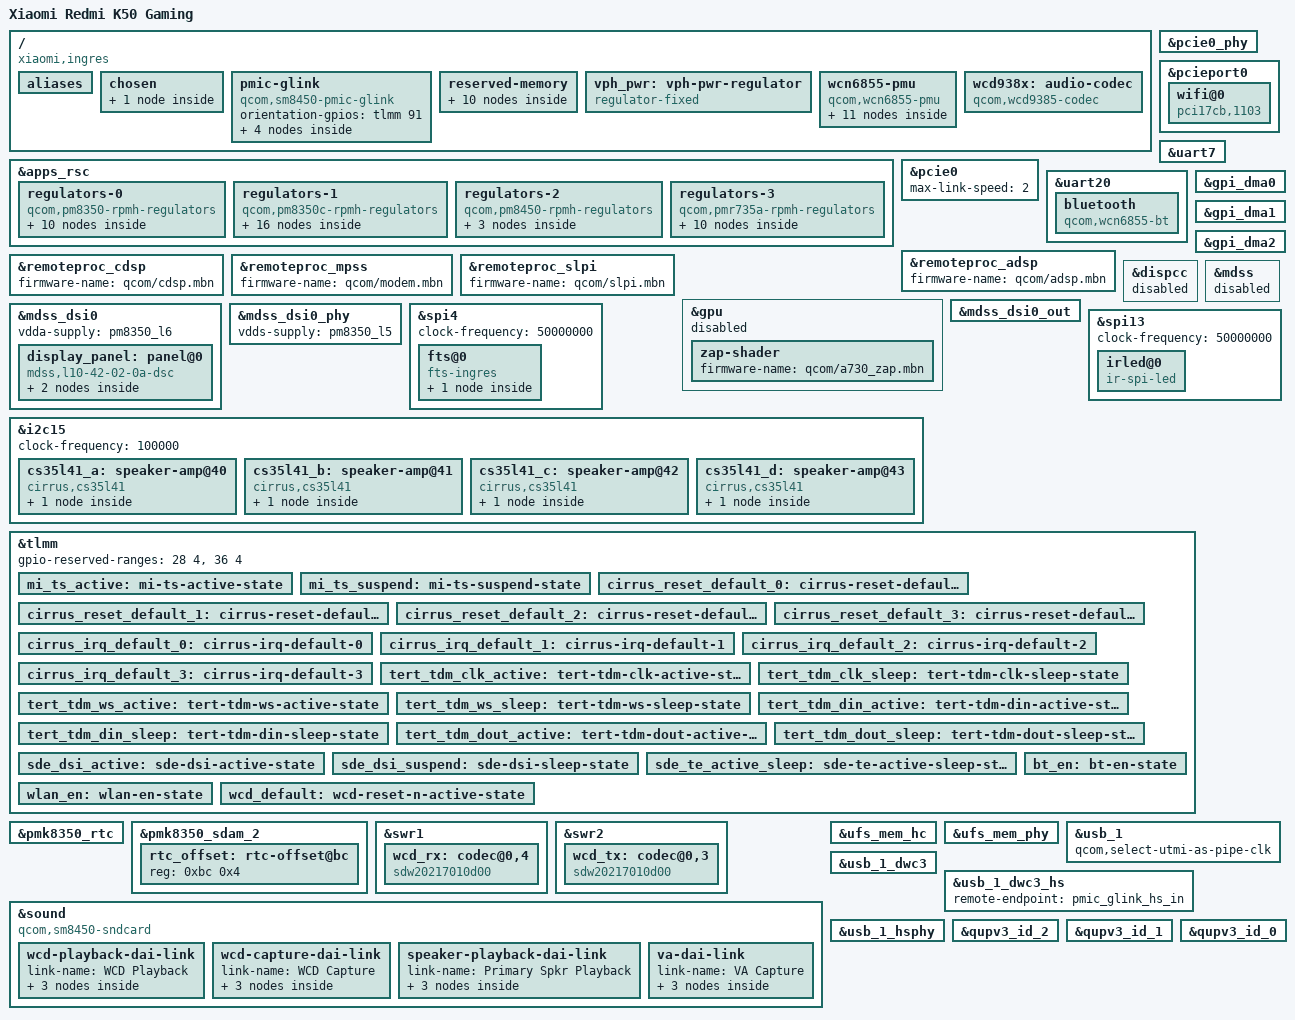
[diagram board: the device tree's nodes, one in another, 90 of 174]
// SPDX-License-Identifier: BSD-3-Clause
/*
 * Copyright (c) 2025, Nika Okromtchedlishvili <okromtchedlishvilinika@gmail.com>
 */
 
/dts-v1/;

#include <dt-bindings/leds/common.h>
#include <dt-bindings/input/linux-event-codes.h>
#include <dt-bindings/gpio/gpio.h>
#include <dt-bindings/interrupt-controller/irq.h>
#include <dt-bindings/regulator/qcom,rpmh-regulator.h>
#include <dt-bindings/leds/common.h>

#include "sm8450.dtsi"
#include "pm8350.dtsi"
#include "pm8350c.dtsi"
#include "pm8450.dtsi"
#include "pmk8350.dtsi"
#include "pmr735a.dtsi"

/delete-node/ &xbl_ramdump_mem;
/delete-node/ &xbl_sc_mem;
/delete-node/ &rmtfs_mem;
/delete-node/ &mte_mem;
/delete-node/ &trusted_apps_mem;
/delete-node/ &trusted_apps_ext_mem;

/delete-node/ &adsp_mem;
/delete-node/ &cdsp_mem;
/delete-node/ &slpi_mem;
/delete-node/ &mpss_mem;
/delete-node/ &spss_region_mem;

/ {
	model = "Xiaomi Redmi K50 Gaming";
	compatible = "xiaomi,ingres", "qcom,sm8450";
	chassis-type = "handset";
	
	aliases {
		serial0 = &uart7;
		serial1 = &uart20;
	};

	chosen {
		#address-cells = <2>;
		#size-cells = <2>;
		ranges;
		
		bootargs = "root=/dev/sda40 rootwait rw earlycon clk_ignore_unused pd_ignore_unused loglevel=8";

		framebuffer: framebuffer@b8000000 {
			compatible = "simple-framebuffer";
			reg = <0x0 0xb8000000 0x0 0x2b00000>;
			width = <1080>;
			height = <2400>;
			stride = <(1080 * 4)>;
			format = "a8r8g8b8";
			//clocks = <&gcc GCC_DISP_HF_AXI_CLK>;
		};
	};
	
	pmic-glink {
		compatible = "qcom,sm8450-pmic-glink", "qcom,pmic-glink";
		#address-cells = <1>;
		#size-cells = <0>;
		orientation-gpios = <&tlmm 91 GPIO_ACTIVE_HIGH>;

		connector@0 {
			compatible = "usb-c-connector";
			reg = <0>;
			power-role = "dual";
			data-role = "dual";

			ports {
				#address-cells = <1>;
				#size-cells = <0>;

				port@0 {
					reg = <0>;

					pmic_glink_hs_in: endpoint {
						remote-endpoint = <&usb_1_dwc3_hs>;
					};
				};
			};
		};
	};

	reserved-memory {
		xbl_ramdump_mem: memory@a6b80000 {
			no-map;
			reg = <0 0xa6b80000 0 0x280000>;
		};

		xbl_sc_mem: memory@a6e00000 {
			no-map;
			reg = <0 0xa6e00000 0 0x40000>;
		};

		framebuffer_mem: framebuffer@b8000000 {
			reg = <0x0 0xb8000000 0x0 0x2b00000>;
			no-map;
		};

		spss_region_mem: memory@8ba00000 {
			no-map;
			reg = <0 0x8ba00000 0 0x180000>;
		};

		adsp_mem: memory@9fd00000 {
			no-map;
			reg = <0 0x9fd00000 0 0x3100000>;
		};

		slpi_mem: memory@88000000 {
			no-map;
			reg = <0 0x88000000 0 0x1900000>;
		};

		cdsp_mem: memory@89900000 {
			no-map;
			reg = <0 0x89900000 0 0x2000000>;
		};

		mpss_mem: memory@8bc00000 {
			no-map;
			reg = <0 0x8bc00000 0 0x13200000>;
		};

		rmtfs_mem: memory@fe200000 {
			compatible = "qcom,rmtfs-mem";
			reg = <0x0 0xfe200000 0x0 0x280000>;
			no-map;

			qcom,client-id = <1>;
			qcom,vmid = <QCOM_SCM_VMID_MSS_MSA>;
		};

		ramoops@a7000000 {
			compatible = "ramoops";
			reg = <0 0xa7000000 0x0 0x400000>;
			console-size = <0x200000>;
			pmsg-size = <0x200000>;
			ecc-size = <16>;
			no-map;
		};
	};

	vph_pwr: vph-pwr-regulator {
		compatible = "regulator-fixed";
		regulator-name = "vph_pwr";
		regulator-min-microvolt = <3700000>;
		regulator-max-microvolt = <3700000>;

		regulator-always-on;
		regulator-boot-on;
	};
	
	wcn6855-pmu {
		compatible = "qcom,wcn6855-pmu";

		pinctrl-0 = <&wlan_en>;
		pinctrl-names = "default";

		wlan-enable-gpios = <&tlmm 80 GPIO_ACTIVE_HIGH>;
		bt-enable-gpios = <&tlmm 81 GPIO_ACTIVE_HIGH>;

		vddio-supply = <&pm8350_s10>;
		vddaon-supply = <&pmr735a_s2>;
		vddpmu-supply = <&pm8350_s11>;
		vddrfa0p95-supply = <&pm8350_s11>;
		vddrfa1p3-supply = <&pm8350_s12>;
		vddrfa1p9-supply = <&pm8350c_s1>;
		vddpcie1p3-supply = <&pm8350_s12>;
		vddpcie1p9-supply = <&pm8350c_s1>;
		

		regulators {
			vreg_pmu_rfa_cmn_0p8: ldo0 {
				regulator-name = "vreg_pmu_rfa_cmn_0p8";
			};

			vreg_pmu_aon_0p8: ldo1 {
				regulator-name = "vreg_pmu_aon_0p8";
			};

			vreg_pmu_wlcx_0p8: ldo2 {
				regulator-name = "vreg_pmu_wlcx_0p8";
			};

			vreg_pmu_wlmx_0p8: ldo3 {
				regulator-name = "vreg_pmu_wlmx_0p8";
			};

			vreg_pmu_btcmx_0p8: ldo4 {
				regulator-name = "vreg_pmu_btcmx_0p8";
			};

			vreg_pmu_pcie_1p8: ldo5 {
				regulator-name = "vreg_pmu_pcie_1p8";
			};

			vreg_pmu_pcie_0p9: ldo6 {
				regulator-name = "vreg_pmu_pcie_0p9";
			};

			vreg_pmu_rfa_0p8: ldo7 {
				regulator-name = "vreg_pmu_rfa_0p8";
			};

			vreg_pmu_rfa_1p2: ldo8 {
				regulator-name = "vreg_pmu_rfa_1p2";
			};

			vreg_pmu_rfa_1p7: ldo9 {
				regulator-name = "vreg_pmu_rfa_1p7";
			};
		};
	};
	
	wcd938x: audio-codec {
		compatible = "qcom,wcd9385-codec";

		pinctrl-names = "default";
		pinctrl-0 = <&wcd_default>;

		qcom,micbias1-microvolt = <2750000>;
		qcom,micbias2-microvolt = <2750000>;
		qcom,micbias3-microvolt = <2750000>;
		qcom,micbias4-microvolt = <2750000>;
		qcom,mbhc-buttons-vthreshold-microvolt = <75000 150000 237000 500000 500000 500000 500000 500000>;
		qcom,mbhc-headset-vthreshold-microvolt = <1700000>;
		qcom,mbhc-headphone-vthreshold-microvolt = <50000>;
		qcom,rx-device = <&wcd_rx>;
		qcom,tx-device = <&wcd_tx>;

		reset-gpios = <&tlmm 43 GPIO_ACTIVE_LOW>;

		vdd-buck-supply = <&pm8350_s10>;
		vdd-rxtx-supply = <&pm8350_s10>;
		vdd-io-supply = <&pm8350_s10>;
		vdd-mic-bias-supply = <&vreg_bob>;

		#sound-dai-cells = <1>;
	};
	
};

&apps_rsc {
	regulators-0 {
		compatible = "qcom,pm8350-rpmh-regulators";
		qcom,pmic-id = "b";

		vdd-s1-supply = <&vph_pwr>;
		vdd-s2-supply = <&vph_pwr>;
		vdd-s3-supply = <&vph_pwr>;
		vdd-s4-supply = <&vph_pwr>;
		vdd-s5-supply = <&vph_pwr>;
		vdd-s6-supply = <&vph_pwr>;
		vdd-s7-supply = <&vph_pwr>;
		vdd-s8-supply = <&vph_pwr>;
		vdd-s9-supply = <&vph_pwr>;
		vdd-s10-supply = <&vph_pwr>;
		vdd-s11-supply = <&vph_pwr>;
		vdd-s12-supply = <&vph_pwr>;

		vdd-l1-l4-supply = <&pm8350_s11>;
		vdd-l2-l7-supply = <&vreg_bob>;
		vdd-l3-l5-supply = <&pm8350_s11>;
		vdd-l6-l9-l10-supply = <&pm8350_s12>;

		/*
		 * ARC regulators:
		 * s5 - gfx.lvl
		 * l8 - lcx.lvl
		 */

		pm8350_s10: smps10 {
			regulator-name = "pm8350_s10";
			regulator-min-microvolt = <1800000>;
			regulator-max-microvolt = <1800000>;
		};

		pm8350_s11: smps11 {
			regulator-name = "pm8350_s11";
			regulator-min-microvolt = <848000>;
			regulator-max-microvolt = <1104000>;
		};

		pm8350_s12: smps12 {
			regulator-name = "pm8350_s12";
			regulator-min-microvolt = <1224000>;
			regulator-max-microvolt = <1400000>;
		};

		pm8350_l1: ldo1 {
			regulator-name = "pm8350_l1";
			regulator-min-microvolt = <912000>;
			regulator-max-microvolt = <920000>;
			regulator-initial-mode = <RPMH_REGULATOR_MODE_HPM>;
		};

		pm8350_l2: ldo2 {
			regulator-name = "pm8350_l2";
			regulator-min-microvolt = <3072000>;
			regulator-max-microvolt = <3072000>;
			regulator-initial-mode = <RPMH_REGULATOR_MODE_HPM>;
		};

		pm8350_l3: ldo3 {
			regulator-name = "pm8350_l3";
			regulator-min-microvolt = <904000>;
			regulator-max-microvolt = <904000>;
			regulator-initial-mode = <RPMH_REGULATOR_MODE_HPM>;
		};

		pm8350_l5: ldo5 {
			regulator-name = "pm8350_l5";
			regulator-min-microvolt = <880000>;
			regulator-max-microvolt = <912000>;
			regulator-initial-mode = <RPMH_REGULATOR_MODE_HPM>;
		};

		pm8350_l6: ldo6 {
			regulator-name = "pm8350_l6";
			regulator-min-microvolt = <1200000>;
			regulator-max-microvolt = <1200000>;
			regulator-initial-mode = <RPMH_REGULATOR_MODE_HPM>;
		};

		pm8350_l7: ldo7 {
			regulator-name = "pm8350_l7";
			regulator-min-microvolt = <2504000>;
			regulator-max-microvolt = <2504000>;
			regulator-initial-mode = <RPMH_REGULATOR_MODE_HPM>;
		};

		pm8350_l9: ldo9 {
			regulator-name = "pm8350_l9";
			regulator-min-microvolt = <1200000>;
			regulator-max-microvolt = <1200000>;
			regulator-initial-mode = <RPMH_REGULATOR_MODE_HPM>;
		};
	};

	regulators-1 {
		compatible = "qcom,pm8350c-rpmh-regulators";
		qcom,pmic-id = "c";

		vdd-s1-supply = <&vph_pwr>;
		vdd-s2-supply = <&vph_pwr>;
		vdd-s3-supply = <&vph_pwr>;
		vdd-s4-supply = <&vph_pwr>;
		vdd-s5-supply = <&vph_pwr>;
		vdd-s6-supply = <&vph_pwr>;
		vdd-s7-supply = <&vph_pwr>;
		vdd-s8-supply = <&vph_pwr>;
		vdd-s9-supply = <&vph_pwr>;
		vdd-s10-supply = <&vph_pwr>;

		vdd-l1-l12-supply = <&pm8350c_s1>;
		vdd-l2-l8-supply = <&pm8350c_s1>;
		vdd-l3-l4-l5-l7-l13-supply = <&vreg_bob>;
		vdd-l6-l9-l11-supply = <&vreg_bob>;
		vdd-l10-supply = <&pm8350_s12>;

		vdd-bob-supply = <&vph_pwr>;

		/*
		 * ARC regulators:
		 * s2 - mxc.lvl
		 * s4 - mss.lvl
		 * s6 - cx.lvl
		 */

		pm8350c_s1: smps1 {
			regulator-name = "pm8350c_s1";
			regulator-min-microvolt = <1800000>;
			regulator-max-microvolt = <2024000>;
		};

		pm8350c_s10: smps10 {
			regulator-name = "pm8350c_s10";
			regulator-min-microvolt = <1000000>;
			regulator-max-microvolt = <1100000>;
		};

		vreg_bob: bob {
			regulator-name = "vreg_bob";
			regulator-min-microvolt = <3080000>;
			regulator-max-microvolt = <3960000>;
			regulator-initial-mode = <RPMH_REGULATOR_MODE_AUTO>;
		};

		pm8350c_l1: ldo1 {
			regulator-name = "pm8350c_l1";
			regulator-min-microvolt = <1800000>;
			regulator-max-microvolt = <1800000>;
			regulator-initial-mode = <RPMH_REGULATOR_MODE_HPM>;
		};

		pm8350c_l2: ldo2 {
			regulator-name = "pm8350c_l2";
			regulator-min-microvolt = <1800000>;
			regulator-max-microvolt = <1800000>;
			regulator-initial-mode = <RPMH_REGULATOR_MODE_HPM>;
		};

		pm8350c_l3: ldo3 {
			regulator-name = "pm8350c_l3";
			regulator-min-microvolt = <3296000>;
			regulator-max-microvolt = <3304000>;
			regulator-initial-mode = <RPMH_REGULATOR_MODE_HPM>;
		};

		pm8350c_l4: ldo4 {
			regulator-name = "pm8350c_l4";
			regulator-min-microvolt = <1704000>;
			regulator-max-microvolt = <3000000>;
			regulator-initial-mode = <RPMH_REGULATOR_MODE_HPM>;
		};

		pm8350c_l5: ldo5 {
			regulator-name = "pm8350c_l5";
			regulator-min-microvolt = <1704000>;
			regulator-max-microvolt = <3000000>;
			regulator-initial-mode = <RPMH_REGULATOR_MODE_HPM>;
		};

		pm8350c_l6: ldo6 {
			regulator-name = "pm8350c_l6";
			regulator-min-microvolt = <1800000>;
			/* Originally max = 3008000 but SDHCI expects 2960000 */
			regulator-max-microvolt = <2960000>;
			regulator-initial-mode = <RPMH_REGULATOR_MODE_HPM>;
		};

		pm8350c_l7: ldo7 {
			regulator-name = "pm8350c_l7";
			regulator-min-microvolt = <3008000>;
			regulator-max-microvolt = <3304000>;
			regulator-initial-mode = <RPMH_REGULATOR_MODE_HPM>;
		};

		pm8350c_l8: ldo8 {
			regulator-name = "pm8350c_l8";
			regulator-min-microvolt = <1800000>;
			regulator-max-microvolt = <1800000>;
			regulator-initial-mode = <RPMH_REGULATOR_MODE_HPM>;
		};

		pm8350c_l9: ldo9 {
			regulator-name = "pm8350c_l9";
			regulator-min-microvolt = <2960000>;
			/* Originally max = 3008000 but SDHCI expects 2960000 */
			regulator-max-microvolt = <2960000>;
			regulator-initial-mode = <RPMH_REGULATOR_MODE_HPM>;
		};

		pm8350c_l10: ldo10 {
			regulator-name = "pm8350c_l10";
			regulator-min-microvolt = <1200000>;
			regulator-max-microvolt = <1220000>;
			regulator-initial-mode = <RPMH_REGULATOR_MODE_HPM>;
		};

		pm8350c_l11: ldo11 {
			regulator-name = "pm8350c_l11";
			regulator-min-microvolt = <3200000>;
			regulator-max-microvolt = <3200000>;
			regulator-initial-mode = <RPMH_REGULATOR_MODE_HPM>;

			regulator-always-on;
			regulator-boot-on;
		};

		pm8350c_l12: ldo12 {
			regulator-name = "pm8350c_l12";
			regulator-min-microvolt = <1800000>;
			regulator-max-microvolt = <1968000>;
			regulator-initial-mode = <RPMH_REGULATOR_MODE_HPM>;
		};

		pm8350c_l13: ldo13 {
			regulator-name = "pm8350c_l13";
			regulator-min-microvolt = <3000000>;
			regulator-max-microvolt = <3000000>;
			regulator-initial-mode = <RPMH_REGULATOR_MODE_HPM>;
		};
	};

	regulators-2 {
		compatible = "qcom,pm8450-rpmh-regulators";
		qcom,pmic-id = "h";

		vdd-s1-supply = <&vph_pwr>;
		vdd-s2-supply = <&vph_pwr>;
		vdd-s3-supply = <&vph_pwr>;
		vdd-s4-supply = <&vph_pwr>;
		vdd-s5-supply = <&vph_pwr>;
		vdd-s6-supply = <&vph_pwr>;

		vdd-l2-supply = <&vreg_bob>;
		vdd-l3-supply = <&vreg_bob>;
		vdd-l4-supply = <&vreg_bob>;

		/*
		 * ARC regulators:
		 * S2 - ebi.lvl
		 * S4 - mmcx.lvl
		 * S6 - mx.lvl
		 * L1 - lmx.lvl
		 */

		pm8450_s3: smps3 {
			regulator-name = "pm8450_s3";
			regulator-min-microvolt = <500000>;
			regulator-max-microvolt = <600000>;
		};

		pm8450_l2: ldo2 {
			regulator-name = "pm8450_l2";
			regulator-min-microvolt = <880000>;
			regulator-max-microvolt = <912000>;
			regulator-initial-mode = <RPMH_REGULATOR_MODE_HPM>;
		};

		pm8450_l3: ldo3 {
			regulator-name = "pm8450_l3";
			regulator-min-microvolt = <912000>;
			regulator-max-microvolt = <912000>;
			regulator-initial-mode = <RPMH_REGULATOR_MODE_HPM>;
		};
	};

	regulators-3 {
		compatible = "qcom,pmr735a-rpmh-regulators";
		qcom,pmic-id = "e";

		vdd-s1-supply = <&vph_pwr>;
		vdd-s2-supply = <&vph_pwr>;
		vdd-s3-supply = <&vph_pwr>;

		vdd-l1-l2-supply = <&pmr735a_s2>;
		vdd-l3-supply = <&pmr735a_s1>;
		vdd-l4-supply = <&pm8350c_s1>;
		vdd-l5-l6-supply = <&pm8350c_s1>;
		vdd-l7-bob-supply = <&vreg_bob>;

		pmr735a_s1: smps1 {
			regulator-name = "pmr735a_s1";
			regulator-min-microvolt = <1200000>;
			regulator-max-microvolt = <1296000>;
		};

		pmr735a_s2: smps2 {
			regulator-name = "pmr735a_s2";
			regulator-min-microvolt = <500000>;
			regulator-max-microvolt = <1040000>;
		};

		pmr735a_s3: smps3 {
			regulator-name = "pmr735a_s3";
			regulator-min-microvolt = <435000>;
			regulator-max-microvolt = <2352000>;
		};

		pmr735a_l1: ldo1 {
			regulator-name = "pmr735a_l1";
			regulator-min-microvolt = <800000>;
			regulator-max-microvolt = <800000>;
		};

		pmr735a_l2: ldo2 {
			regulator-name = "pmr735a_l2";
			regulator-min-microvolt = <480000>;
			regulator-max-microvolt = <912000>;
		};

		pmr735a_l3: ldo3 {
			regulator-name = "pmr735a_l3";
			regulator-min-microvolt = <1200000>;
			regulator-max-microvolt = <1200000>;
		};

		pmr735a_l4: ldo4 {
			regulator-name = "pmr735a_l4";
			regulator-min-microvolt = <1776000>;
			regulator-max-microvolt = <1776000>;
		};

		pmr735a_l5: ldo5 {
			regulator-name = "pmr735a_l5";
			regulator-min-microvolt = <880000>;
			regulator-max-microvolt = <880000>;
		};

		pmr735a_l6: ldo6 {
			regulator-name = "pmr735a_l6";
			regulator-min-microvolt = <1200000>;
			regulator-max-microvolt = <1200000>;
		};

		pmr735a_l7: ldo7 {
			regulator-name = "pmr735a_l7";
			regulator-min-microvolt = <2800000>;
			regulator-max-microvolt = <2800000>;
		};
	};
};

&pcie0 {
	status = "okay";
	max-link-speed = <2>;
};

&pcie0_phy {
	status = "okay";
	vdda-phy-supply = <&pm8350_l5>;
	vdda-pll-supply = <&pm8350_l6>;
};

&pcieport0 {
	wifi@0 {
		compatible = "pci17cb,1103";
		reg = <0x10000 0x0 0x0 0x0 0x0>;

		vddrfacmn-supply = <&vreg_pmu_rfa_cmn_0p8>;
		vddaon-supply = <&vreg_pmu_aon_0p8>;
		vddwlcx-supply = <&vreg_pmu_wlcx_0p8>;
		vddwlmx-supply = <&vreg_pmu_wlmx_0p8>;
		vddpcie1p8-supply = <&vreg_pmu_pcie_1p8>;
		vddpcie0p9-supply = <&vreg_pmu_pcie_0p9>;
		vddrfa0p8-supply = <&vreg_pmu_rfa_0p8>;
		vddrfa1p2-supply = <&vreg_pmu_rfa_1p2>;
		vddrfa1p8-supply = <&vreg_pmu_rfa_1p7>;
	};
};

&uart7 {
	status = "okay";
};

&uart20 {
	status = "okay";

	bluetooth {
		compatible = "qcom,wcn6855-bt";

		vddrfacmn-supply = <&vreg_pmu_rfa_cmn_0p8>;
		vddaon-supply = <&vreg_pmu_aon_0p8>;
		vddwlcx-supply = <&vreg_pmu_wlcx_0p8>;
		vddwlmx-supply = <&vreg_pmu_wlmx_0p8>;
		vddbtcmx-supply = <&vreg_pmu_btcmx_0p8>;
		vddrfa0p8-supply = <&vreg_pmu_rfa_0p8>;
		vddrfa1p2-supply = <&vreg_pmu_rfa_1p2>;
		vddrfa1p8-supply = <&vreg_pmu_rfa_1p7>;

		max-speed = <3200000>;
	};
};

&remoteproc_adsp {
	firmware-name = "qcom/adsp.mbn";
	status = "okay";
};

&remoteproc_cdsp {
	firmware-name = "qcom/cdsp.mbn";
	status = "okay";
};

&remoteproc_mpss {
	firmware-name = "qcom/modem.mbn";
	status = "okay";
};

&remoteproc_slpi {
	firmware-name = "qcom/slpi.mbn";
	status = "okay";
};

&gpi_dma0 {
	status = "okay";
};

&gpi_dma1 {
	status = "okay";
};

&gpi_dma2 {
	status = "okay";
};

&gpu {
	status = "disabled";

	zap-shader {
		firmware-name = "qcom/a730_zap.mbn";
	};
};

&dispcc {
	status = "disabled";
};

&mdss {
	status = "disabled";
};

&mdss_dsi0 {
	vdda-supply = <&pm8350_l6>;
	status = "okay";

	display_panel: panel@0 {
		compatible = "mdss,l10-42-02-0a-dsc";
		reg = <0>;

		reset-gpios = <&tlmm 0 GPIO_ACTIVE_LOW>;
		te-gpios = <&tlmm 86 GPIO_ACTIVE_HIGH>;

		pinctrl-0 = <&sde_dsi_active &sde_te_active_sleep>;
		pinctrl-1 = <&sde_dsi_suspend &sde_te_active_sleep>;
		pinctrl-names = "default", "sleep";

		vddd-supply = <&pm8350c_l10>;
		vci-supply = <&pm8350c_l13>;
		vddio-supply = <&pm8350c_l12>;

		port {
			panel_in: endpoint {
				remote-endpoint = <&mdss_dsi0_out>;
			};
		};
	};
};

&mdss_dsi0_out {
	data-lanes = <0 1 2 3>;
	remote-endpoint = <&panel_in>;
};

&mdss_dsi0_phy {
	vdds-supply = <&pm8350_l5>;
	status = "okay";
};

&spi4 {
	clock-frequency = <50000000>;
	status = "okay";

	fts@0 {
	    status = "okay";
		compatible = "fts-ingres";
		reg = <0x0>;
		interrupt-parent = <&tlmm>;
		interrupts = <21 IRQ_TYPE_LEVEL_LOW>;
		pinctrl-names = "pmx_ts_active", "pmx_ts_suspend";
		pinctrl-0 = <&mi_ts_active>;
		pinctrl-1 = <&mi_ts_suspend>;
		avdd-supply = <&pm8350c_l3>;
		vdd-supply = <&pm8350c_l2>;
		fts,pwr-reg-name = "avdd";
		fts,bus-reg-name = "vdd";
		fts,irq-gpio = <&tlmm 21 IRQ_TYPE_LEVEL_LOW>;
		fts,reset-gpio-enable;
		fts,reset-gpio = <&tlmm 20 GPIO_ACTIVE_HIGH>;
		fts,irq-flags = <IRQ_TYPE_LEVEL_LOW>;
		fts,x-max = <10800>;
		fts,y-max = <24000>;
		fts,support-super-resolution = <1>;
		spi-max-frequency = <12000000>;
		fts,default-fw-name = "st_fts_l10.ftb";
		fts,config-array-size = <1>;
		panel = <&display_panel>;

		fts,cfg_0 {
			fts,tp-vendor = <0x42>;
			fts,fw-name = "st_fts_l10.ftb";
			fts,limit-name = "stm_fts_production_limits.csv";
		};
	};
};

&spi13 {
	clock-frequency = <50000000>;
	status = "okay";

	irled@0 {
		compatible = "ir-spi-led";
		reg = <0x0>;
		power-supply = <&vph_pwr>;
		spi-max-frequency = <19200000>;
	};
};

&i2c15 {
	clock-frequency = <100000>;
	status = "okay";

	cs35l41_a: speaker-amp@40 {
		compatible = "cirrus,cs35l41";
		reg = <0x40>;
		interrupt-parent = <&tlmm>;
		interrupts = <117 0x2008>;
		pinctrl-names = "default";
		pinctrl-0 = <&cirrus_reset_default_0 &cirrus_irq_default_0>;
		reset-gpios = <&tlmm 120 0>;
		cirrus,boost-peak-milliamp = <4000>;
		cirrus,boost-ind-nanohenry = <1000>;
		cirrus,boost-cap-microfarad = <15>;
		cirrus,gpio2-src-select = <4>;
		cirrus,gpio2-output-enable;
		cirrus,asp-sdout-hiz = <3>;
		cirrus,fast-switch = "BH-music.txt", "BH-handfree.txt";
		sound-name-prefix = "BH";
		#sound-dai-cells = <1>;
		cirrus,gpio-config2 {
			cirrus,gpio-src-select = <0x04>;
			cirrus,gpio-output-enable;
		};
	};
	
	cs35l41_b: speaker-amp@41 {
		compatible = "cirrus,cs35l41";
		reg = <0x41>;
		interrupt-parent = <&tlmm>;
		interrupts = <118 0x2008>;
		pinctrl-names = "default";
		pinctrl-0 = <&cirrus_reset_default_1 &cirrus_irq_default_1>;
		reset-gpios = <&tlmm 9 0>;
		cirrus,boost-peak-milliamp = <4000>;
		cirrus,boost-ind-nanohenry = <1000>;
		cirrus,boost-cap-microfarad = <15>;
		cirrus,gpio2-src-select = <4>;
		cirrus,gpio2-output-enable;
		cirrus,asp-sdout-hiz = <3>;
		cirrus,right-channel-amp;
		cirrus,fast-switch = "BL-music.txt", "BL-handfree.txt";
		sound-name-prefix = "BL";
		#sound-dai-cells = <1>;
		cirrus,gpio-config2 {
			cirrus,gpio-src-select = <0x04>;
			cirrus,gpio-output-enable;
		};
	};

	cs35l41_c: speaker-amp@42 {
		compatible = "cirrus,cs35l41";
		reg = <0x42>;
		interrupt-parent = <&tlmm>;
		interrupts = <63 0x2008>;
		pinctrl-names = "default";
		pinctrl-0 = <&cirrus_reset_default_2 &cirrus_irq_default_2>;
		reset-gpios = <&tlmm 3 0>;
		cirrus,boost-peak-milliamp = <4000>;
		cirrus,boost-ind-nanohenry = <1000>;
		cirrus,boost-cap-microfarad = <15>;
		cirrus,gpio2-src-select = <4>;
		cirrus,gpio2-output-enable;
		cirrus,asp-sdout-hiz = <3>;
		cirrus,fast-switch = "TH-music.txt", "TH-handfree.txt";
		sound-name-prefix = "TH";
		#sound-dai-cells = <1>;
		cirrus,gpio-config2 {
			cirrus,gpio-src-select = <0x04>;
			cirrus,gpio-output-enable;
		};
	};
	
	cs35l41_d: speaker-amp@43 {
		compatible = "cirrus,cs35l41";
		reg = <0x43>;
		interrupt-parent = <&tlmm>;
		interrupts = <88 0x2008>;
		pinctrl-names = "default";
		pinctrl-0 = <&cirrus_reset_default_3 &cirrus_irq_default_3>;
		reset-gpios = <&tlmm 1 0>;
		spk-sw-gpios = <&tlmm 52 0x00>;
		cirrus,boost-peak-milliamp = <4000>;
		cirrus,boost-ind-nanohenry = <1000>;
		cirrus,boost-cap-microfarad = <15>;
		cirrus,gpio2-src-select = <4>;
		cirrus,gpio2-output-enable;
		cirrus,asp-sdout-hiz = <3>;
		cirrus,fast-switch = "TL-music.txt", "TL-handset.txt", "TL-handfree.txt";
		sound-name-prefix = "TL";
		#sound-dai-cells = <1>;
		cirrus,gpio-config2 {
			cirrus,gpio-src-select = <0x04>;
			cirrus,gpio-output-enable;
		};
	};
};

&tlmm {
	gpio-reserved-ranges = <28 4>, <36 4>;
	
	mi_ts_active: mi-ts-active-state {
		pins = "gpio20", "gpio21";
		function = "gpio";
		drive-strength = <8>;
		bias-pull-up;
	};

	mi_ts_suspend: mi-ts-suspend-state {
		pins = "gpio20", "gpio21";
		function = "gpio";
		drive-strength = <2>;
		bias-pull-down;
	};
	
	cirrus_reset_default_0: cirrus-reset-default-0 {
		pins = "gpio120";
		function = "gpio";
		drive-strength = <16>;
		bias-disable;
		output-high;
	};
	
	cirrus_reset_default_1: cirrus-reset-default-1 {
		pins = "gpio9";
		function = "gpio";
		drive-strength = <16>;
		bias-disable;
		output-high;
	};
	
	cirrus_reset_default_2: cirrus-reset-default-2 {
		pins = "gpio3";
		function = "gpio";
		drive-strength = <16>;
		bias-disable;
		output-high;
	};
	
	cirrus_reset_default_3: cirrus-reset-default-3 {
		pins = "gpio1";
		function = "gpio";
		drive-strength = <16>;
		bias-disable;
		output-high;
	};

	cirrus_irq_default_0: cirrus-irq-default-0 {
		pins = "gpio117";
		function = "gpio";
		drive-strength = <2>;
		input-enable;
		bias-pull-up;
	};

	cirrus_irq_default_1: cirrus-irq-default-1 {
		pins = "gpio118";
		function = "gpio";
		drive-strength = <2>;
		input-enable;
		bias-pull-up;
	};
	
	cirrus_irq_default_2: cirrus-irq-default-2 {
		pins = "gpio63";
		function = "gpio";
		drive-strength = <2>;
		input-enable;
		bias-pull-up;
	};
	
	cirrus_irq_default_3: cirrus-irq-default-3 {
		pins = "gpio88";
		function = "gpio";
		drive-strength = <2>;
		input-enable;
		bias-pull-up;
	};
	
	tert_tdm_clk_active: tert-tdm-clk-active-state {
		pins = "gpio121";
		function = "mi2s2_sck";
		drive-strength = <6>;
		bias-disable;
		output-high;
	};

	tert_tdm_clk_sleep: tert-tdm-clk-sleep-state {
		pins = "gpio121";
		function = "gpio";
		drive-strength = <2>;
		bias-pull-down;
		input-enable;
	};

	tert_tdm_ws_active: tert-tdm-ws-active-state {
		pins = "gpio123";
		function = "mi2s2_ws";
		drive-strength = <8>;
		bias-disable;
		output-high;
	};

	tert_tdm_ws_sleep: tert-tdm-ws-sleep-state {
		pins = "gpio123";
		function = "gpio";
		drive-strength = <2>;
		bias-pull-down;
		input-enable;
	};

	tert_tdm_din_active: tert-tdm-din-active-state {
		pins = "gpio122";
		function = "mi2s2_data0";
		drive-strength = <8>;
		bias-disable;
	};

	tert_tdm_din_sleep: tert-tdm-din-sleep-state {
		pins = "gpio122";
		function = "gpio";
		drive-strength = <2>;
		bias-pull-down;
		input-enable;
	};

	tert_tdm_dout_active: tert-tdm-dout-active-state {
		pins = "gpio124";
		function = "mi2s2_data1";
		drive-strength = <8>;
		bias-disable;
	};

	tert_tdm_dout_sleep: tert-tdm-dout-sleep-state {
		pins = "gpio124";
		function = "gpio";
		drive-strength = <2>;
		bias-pull-down;
		input-enable;
	};
	
	sde_dsi_active: sde-dsi-active-state {
		pins = "gpio0";
		function = "gpio";
		drive-strength = <16>;
		bias-disable;
	};

	sde_dsi_suspend: sde-dsi-sleep-state {
		pins = "gpio0";
		function = "gpio";
		drive-strength = <2>;
		bias-pull-down;
	};

	sde_te_active_sleep: sde-te-active-sleep-state {
		pins = "gpio86";
		function = "mdp_vsync";
		drive-strength = <2>;
		bias-pull-down;
	};
	
	bt_en: bt-en-state {
		pins = "gpio81";
		function = "gpio";
		drive-strength = <16>;
		output-low;
		bias-pull-down;
	};

	wlan_en: wlan-en-state {
		pins = "gpio80";
		function = "gpio";
		drive-strength = <16>;
		bias-disable;
		output-low;
	};
	
	wcd_default: wcd-reset-n-active-state {
		pins = "gpio43";
		function = "gpio";
		drive-strength = <16>;
		bias-disable;
		output-low;
	};
};

&pmk8350_rtc {
	nvmem-cells = <&rtc_offset>;
	nvmem-cell-names = "offset";

	status = "okay";
};

&pmk8350_sdam_2 {
	status = "okay";

	rtc_offset: rtc-offset@bc {
		reg = <0xbc 0x4>;
	};
};

&swr1 {
	status = "okay";

	/* WCD9380 RX */
	wcd_rx: codec@0,4 {
		compatible = "sdw20217010d00";
		reg = <0 4>;
		qcom,rx-port-mapping = <1 2 3 4 5>;
	};
};

&swr2 {
	status = "okay";

	/* WCD9380 TX */
	wcd_tx: codec@0,3 {
		compatible = "sdw20217010d00";
		reg = <0 3>;
		qcom,tx-port-mapping = <1 1 2 3>;
	};
};

&sound {
	compatible = "qcom,sm8450-sndcard";
	pinctrl-names = "default", "sleep";
	pinctrl-0 = <&tert_tdm_clk_active &tert_tdm_ws_active
			&tert_tdm_din_active &tert_tdm_dout_active>;
	pinctrl-1 = <&tert_tdm_clk_sleep &tert_tdm_ws_sleep
			&tert_tdm_din_sleep &tert_tdm_dout_sleep>;
	model = "Xiaomi-POCO-F4-GT";
	/*
	audio-routing = "AMIC1", "Analog Mic1",
		"AMIC1", "MIC BIAS1",
		"AMIC2", "Analog Mic2",
		"AMIC2", "MIC BIAS2",
		"AMIC3", "Analog Mic3",
		"AMIC3", "MIC BIAS3",
		"AMIC4", "Analog Mic4",
		"AMIC4", "MIC BIAS3",
		"AMIC5", "Analog Mic5",
		"AMIC5", "MIC BIAS4",
		"VA AMIC1", "Analog Mic1",
		"VA AMIC1", "VA MIC BIAS1",
		"VA AMIC2", "Analog Mic2",
		"VA AMIC2", "VA MIC BIAS2",
		"VA AMIC3", "Analog Mic3",
		"VA AMIC3", "VA MIC BIAS3",
		"VA AMIC4", "Analog Mic4",
		"VA AMIC4", "VA MIC BIAS3",
		"VA AMIC5", "Analog Mic5",
		"VA AMIC5", "VA MIC BIAS4",
		"TX DMIC0", "Digital Mic0",
		"Digital Mic0", "MIC BIAS3",
		"TX DMIC1", "Digital Mic1",
		"Digital Mic1", "MIC BIAS3",
		"TX DMIC2", "Digital Mic2",
		"Digital Mic2", "MIC BIAS1",
		"TX DMIC3", "Digital Mic3",
		"Digital Mic3", "MIC BIAS1",
		"IN1_HPHL", "HPHL_OUT",
		"IN2_HPHR", "HPHR_OUT",
		"IN3_AUX", "AUX_OUT",
		"RX_TX DEC0_INP", "TX DEC0 MUX",
		"RX_TX DEC1_INP", "TX DEC1 MUX",
		"RX_TX DEC2_INP", "TX DEC2 MUX",
		"RX_TX DEC3_INP", "TX DEC3 MUX",
		"TX SWR_INPUT", "WCD_TX_OUTPUT",
		"VA SWR_INPUT", "VA_SWR_CLK",
		"VA SWR_INPUT", "WCD_TX_OUTPUT",
		"VA_AIF1 CAP", "VA_SWR_CLK",
		"VA_AIF2 CAP", "VA_SWR_CLK",
		"VA_AIF3 CAP", "VA_SWR_CLK",
		"VA DMIC0", "Digital Mic0",
		"VA DMIC1", "Digital Mic1",
		"VA DMIC2", "Digital Mic2",
		"VA DMIC3", "Digital Mic3",
		"Digital Mic0", "VA MIC BIAS3",
		"Digital Mic1", "VA MIC BIAS3",
		"Digital Mic2", "VA MIC BIAS1",
		"Digital Mic3", "VA MIC BIAS1";
	*/

	wcd-playback-dai-link {
		link-name = "WCD Playback";

		cpu {
			sound-dai = <&q6apmbedai RX_CODEC_DMA_RX_0>;
		};

		codec {
			sound-dai = <&wcd938x 0>, <&swr1 0>, <&rxmacro 0>;
		};

		platform {
			sound-dai = <&q6apm>;
		};
	};

	wcd-capture-dai-link {
		link-name = "WCD Capture";

		cpu {
			sound-dai = <&q6apmbedai TX_CODEC_DMA_TX_3>;
		};

		codec {
			sound-dai = <&wcd938x 1>, <&swr2 0>, <&txmacro 0>;
		};

		platform {
			sound-dai = <&q6apm>;
		};
	};

	speaker-playback-dai-link {
		link-name = "Primary Spkr Playback";

		cpu {
			sound-dai = <&q6apmbedai TERTIARY_TDM_RX_0>;
		};

		codec {
			sound-dai = <&cs35l41_a 0>, <&cs35l41_b 0>, <&cs35l41_c 0>, <&cs35l41_d 0>;
		};

		platform {
			sound-dai = <&q6apm>;
		};
	};

	va-dai-link {
		link-name = "VA Capture";

		cpu {
			sound-dai = <&q6apmbedai TX_CODEC_DMA_TX_3>;
		};

		codec {
			sound-dai = <&vamacro 0>;
		};

		platform {
			sound-dai = <&q6apm>;
		};
	};
};

&ufs_mem_hc {
	status = "okay";

	reset-gpios = <&tlmm 210 GPIO_ACTIVE_LOW>;

	vcc-supply = <&pm8350_l7>;
	vcc-max-microamp = <1100000>;
	vccq-supply = <&pm8350_l9>;
	vccq-max-microamp = <1200000>;
	vdd-hba-supply = <&pm8350_l9>;
};

&ufs_mem_phy {
	status = "okay";

	vdda-phy-supply = <&pm8350_l5>;
	vdda-pll-supply = <&pm8350_l6>;
};

&usb_1 {
	qcom,select-utmi-as-pipe-clk;
	status = "okay";
};

&usb_1_dwc3 {
	dr_mode = "host";
	maximum-speed = "high-speed";
	usb-role-switch;
	phys = <&usb_1_hsphy>;
	phy-names = "usb2-phy";
};

&usb_1_dwc3_hs {
	remote-endpoint = <&pmic_glink_hs_in>;
};

&usb_1_hsphy {
    status = "okay";

    vdda-pll-supply = <&pm8350_l5>;
	vdda18-supply = <&pm8350c_l1>;
	vdda33-supply = <&pm8350_l2>;
};

&qupv3_id_2 {
	status = "okay";
};

&qupv3_id_1 {
	status = "okay";
};

&qupv3_id_0 {
	status = "okay";
};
